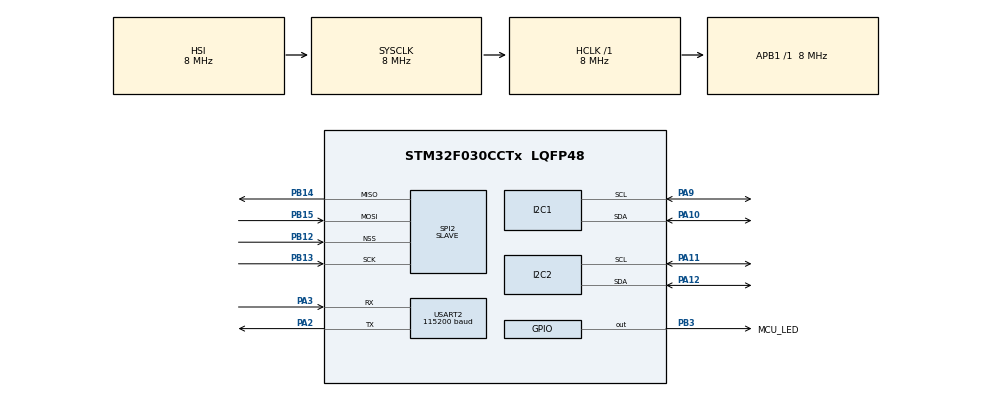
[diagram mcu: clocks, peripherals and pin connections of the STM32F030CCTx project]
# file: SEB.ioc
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I2C1.Timing=0x00201D2B
Mcu.Family=STM32F0
Mcu.Name=STM32F030CCTx
Mcu.Package=LQFP48
NVIC.SPI2_IRQn=true\:0\:0\:false\:false\:true\:true\:false\:false
PA10.Mode=I2C
PA10.Signal=I2C1_SDA
PA11.Mode=I2C
PA11.Signal=I2C2_SCL
PA12.Mode=I2C
PA12.Signal=I2C2_SDA
PA2.Mode=Asynchronous
PA2.Signal=USART2_TX
PA3.Mode=Asynchronous
PA3.Signal=USART2_RX
PA9.Mode=I2C
PA9.Signal=I2C1_SCL
PB12.GPIO_Mode=GPIO_MODE_AF_PP
PB12.GPIO_PuPd=GPIO_NOPULL
PB12.GPIO_Speed=GPIO_SPEED_FREQ_HIGH
PB12.Mode=NSS_Signal_Hard_Input
PB12.Signal=SPI2_NSS
PB13.GPIO_Mode=GPIO_MODE_AF_PP
PB13.GPIO_PuPd=GPIO_PULLDOWN
PB13.GPIO_Speed=GPIO_SPEED_FREQ_HIGH
PB13.Mode=Full_Duplex_Slave
PB13.Signal=SPI2_SCK
PB14.GPIO_Mode=GPIO_MODE_AF_PP
PB14.GPIO_PuPd=GPIO_NOPULL
PB14.GPIO_Speed=GPIO_SPEED_FREQ_HIGH
PB14.Mode=Full_Duplex_Slave
PB14.Signal=SPI2_MISO
PB15.GPIO_Mode=GPIO_MODE_AF_PP
PB15.GPIO_PuPd=GPIO_NOPULL
PB15.GPIO_Speed=GPIO_SPEED_FREQ_HIGH
PB15.Mode=Full_Duplex_Slave
PB15.Signal=SPI2_MOSI
PB3.GPIO_Label=MCU_LED
PB3.Signal=GPIO_Output
ProjectManager.HeapSize=0x200
ProjectManager.StackSize=0x400
ProjectManager.TargetToolchain=STM32CubeIDE
RCC.AHBFreq_Value=8000000
RCC.APB1Freq_Value=8000000
RCC.APB1TimFreq_Value=8000000
RCC.HCLKFreq_Value=8000000
RCC.HSE_VALUE=30000000
RCC.SYSCLKFreq_VALUE=8000000
SPI2.DataSize=SPI_DATASIZE_8BIT
SPI2.Direction=SPI_DIRECTION_2LINES
SPI2.Mode=SPI_MODE_SLAVE
SPI2.VirtualNSS=VM_NSSHARD
SPI2.VirtualType=VM_SLAVE
USART2.BaudRate=115200
USART2.SwapParam=ADVFEATURE_SWAP_ENABLE
USART2.VirtualMode-Asynchronous=VM_ASYNC
board=custom

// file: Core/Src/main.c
/* USER CODE BEGIN Header */
/**
  ******************************************************************************
  * @file           : main.c
  * @brief          : Main program body
  ******************************************************************************
  * @attention
  *
  * Copyright (c) 2024 STMicroelectronics.
  * All rights reserved.
  *
  * This software is licensed under terms that can be found in the LICENSE file
  * in the root directory of this software component.
  * If no LICENSE file comes with this software, it is provided AS-IS.
  *
  ******************************************************************************
  */
/* USER CODE END Header */
#include "main.h"

/* USER CODE BEGIN Includes */
#include "MS5611_SIM.h"
/* USER CODE END Includes */

I2C_HandleTypeDef hi2c1;
I2C_HandleTypeDef hi2c2;

SPI_HandleTypeDef hspi2;

UART_HandleTypeDef huart2;

void SystemClock_Config(void);
static void MX_GPIO_Init(void);
static void MX_USART2_UART_Init(void);
static void MX_I2C1_Init(void);
static void MX_I2C2_Init(void);
static void MX_SPI2_Init(void);

int main(void)
{

  /* MCU Configuration--------------------------------------------------------*/

  /* Reset of all peripherals, Initializes the Flash interface and the Systick. */
  HAL_Init();

  /* Configure the system clock */
  SystemClock_Config();

  /* Initialize all configured peripherals */
  MX_GPIO_Init();
  MX_USART2_UART_Init();
  MX_I2C1_Init();
  MX_I2C2_Init();
  MX_SPI2_Init();
  /* USER CODE BEGIN 2 */
  emulation_init();
  /* USER CODE END 2 */

  /* Infinite loop */
  while (1) {

  }
}

void SystemClock_Config(void)
{
  RCC_OscInitTypeDef RCC_OscInitStruct = {0};
  RCC_ClkInitTypeDef RCC_ClkInitStruct = {0};
  RCC_PeriphCLKInitTypeDef PeriphClkInit = {0};

  /** Initializes the RCC Oscillators according to the specified parameters
  * in the RCC_OscInitTypeDef structure.
  */
  RCC_OscInitStruct.OscillatorType = RCC_OSCILLATORTYPE_HSI;
  RCC_OscInitStruct.HSIState = RCC_HSI_ON;
  RCC_OscInitStruct.HSICalibrationValue = RCC_HSICALIBRATION_DEFAULT;
  RCC_OscInitStruct.PLL.PLLState = RCC_PLL_NONE;
  if (HAL_RCC_OscConfig(&RCC_OscInitStruct) != HAL_OK)
  {
    Error_Handler();
  }

  /** Initializes the CPU, AHB and APB buses clocks
  */
  RCC_ClkInitStruct.ClockType = RCC_CLOCKTYPE_HCLK|RCC_CLOCKTYPE_SYSCLK
                              |RCC_CLOCKTYPE_PCLK1;
  RCC_ClkInitStruct.SYSCLKSource = RCC_SYSCLKSOURCE_HSI;
  RCC_ClkInitStruct.AHBCLKDivider = RCC_SYSCLK_DIV1;
  RCC_ClkInitStruct.APB1CLKDivider = RCC_HCLK_DIV1;

  if (HAL_RCC_ClockConfig(&RCC_ClkInitStruct, FLASH_LATENCY_0) != HAL_OK)
  {
    Error_Handler();
  }
  PeriphClkInit.PeriphClockSelection = RCC_PERIPHCLK_I2C1;
  PeriphClkInit.I2c1ClockSelection = RCC_I2C1CLKSOURCE_HSI;
  if (HAL_RCCEx_PeriphCLKConfig(&PeriphClkInit) != HAL_OK)
  {
    Error_Handler();
  }
}

static void MX_I2C1_Init(void)
{

  hi2c1.Instance = I2C1;
  hi2c1.Init.Timing = 0x00201D2B;
  hi2c1.Init.OwnAddress1 = 0;
  hi2c1.Init.AddressingMode = I2C_ADDRESSINGMODE_7BIT;
  hi2c1.Init.DualAddressMode = I2C_DUALADDRESS_DISABLE;
  hi2c1.Init.OwnAddress2 = 0;
  hi2c1.Init.OwnAddress2Masks = I2C_OA2_NOMASK;
  hi2c1.Init.GeneralCallMode = I2C_GENERALCALL_DISABLE;
  hi2c1.Init.NoStretchMode = I2C_NOSTRETCH_DISABLE;
  if (HAL_I2C_Init(&hi2c1) != HAL_OK)
  {
    Error_Handler();
  }

  /** Configure Analogue filter
  */
  if (HAL_I2CEx_ConfigAnalogFilter(&hi2c1, I2C_ANALOGFILTER_ENABLE) != HAL_OK)
  {
    Error_Handler();
  }

  /** Configure Digital filter
  */
  if (HAL_I2CEx_ConfigDigitalFilter(&hi2c1, 0) != HAL_OK)
  {
    Error_Handler();
  }

}

static void MX_I2C2_Init(void)
{

  hi2c2.Instance = I2C2;
  hi2c2.Init.Timing = 0x2000090E;
  hi2c2.Init.OwnAddress1 = 0;
  hi2c2.Init.AddressingMode = I2C_ADDRESSINGMODE_7BIT;
  hi2c2.Init.DualAddressMode = I2C_DUALADDRESS_DISABLE;
  hi2c2.Init.OwnAddress2 = 0;
  hi2c2.Init.OwnAddress2Masks = I2C_OA2_NOMASK;
  hi2c2.Init.GeneralCallMode = I2C_GENERALCALL_DISABLE;
  hi2c2.Init.NoStretchMode = I2C_NOSTRETCH_DISABLE;
  if (HAL_I2C_Init(&hi2c2) != HAL_OK)
  {
    Error_Handler();
  }

  /** Configure Analogue filter
  */
  if (HAL_I2CEx_ConfigAnalogFilter(&hi2c2, I2C_ANALOGFILTER_ENABLE) != HAL_OK)
  {
    Error_Handler();
  }

  /** Configure Digital filter
  */
  if (HAL_I2CEx_ConfigDigitalFilter(&hi2c2, 0) != HAL_OK)
  {
    Error_Handler();
  }

}

static void MX_SPI2_Init(void)
{

  /* SPI2 parameter configuration*/
  hspi2.Instance = SPI2;
  hspi2.Init.Mode = SPI_MODE_SLAVE;
  hspi2.Init.Direction = SPI_DIRECTION_2LINES;
  hspi2.Init.DataSize = SPI_DATASIZE_8BIT;
  hspi2.Init.CLKPolarity = SPI_POLARITY_LOW;
  hspi2.Init.CLKPhase = SPI_PHASE_1EDGE;
  hspi2.Init.NSS = SPI_NSS_HARD_INPUT;
  hspi2.Init.FirstBit = SPI_FIRSTBIT_MSB;
  hspi2.Init.TIMode = SPI_TIMODE_DISABLE;
  hspi2.Init.CRCCalculation = SPI_CRCCALCULATION_DISABLE;
  hspi2.Init.CRCPolynomial = 7;
  hspi2.Init.CRCLength = SPI_CRC_LENGTH_DATASIZE;
  hspi2.Init.NSSPMode = SPI_NSS_PULSE_DISABLE;
  if (HAL_SPI_Init(&hspi2) != HAL_OK)
  {
    Error_Handler();
  }

}

static void MX_USART2_UART_Init(void)
{

  huart2.Instance = USART2;
  huart2.Init.BaudRate = 115200;
  huart2.Init.WordLength = UART_WORDLENGTH_8B;
  huart2.Init.StopBits = UART_STOPBITS_1;
  huart2.Init.Parity = UART_PARITY_NONE;
  huart2.Init.Mode = UART_MODE_TX_RX;
  huart2.Init.HwFlowCtl = UART_HWCONTROL_NONE;
  huart2.Init.OverSampling = UART_OVERSAMPLING_16;
  huart2.Init.OneBitSampling = UART_ONE_BIT_SAMPLE_DISABLE;
  huart2.AdvancedInit.AdvFeatureInit = UART_ADVFEATURE_SWAP_INIT;
  huart2.AdvancedInit.Swap = UART_ADVFEATURE_SWAP_ENABLE;
  if (HAL_UART_Init(&huart2) != HAL_OK)
  {
    Error_Handler();
  }

}

static void MX_GPIO_Init(void)
{
  GPIO_InitTypeDef GPIO_InitStruct = {0};

  /* GPIO Ports Clock Enable */
  __HAL_RCC_GPIOA_CLK_ENABLE();
  __HAL_RCC_GPIOB_CLK_ENABLE();

  /*Configure GPIO pin Output Level */
  HAL_GPIO_WritePin(MCU_LED_GPIO_Port, MCU_LED_Pin, GPIO_PIN_RESET);

  /*Configure GPIO pin : MCU_LED_Pin */
  GPIO_InitStruct.Pin = MCU_LED_Pin;
  GPIO_InitStruct.Mode = GPIO_MODE_OUTPUT_PP;
  GPIO_InitStruct.Pull = GPIO_NOPULL;
  GPIO_InitStruct.Speed = GPIO_SPEED_FREQ_LOW;
  HAL_GPIO_Init(MCU_LED_GPIO_Port, &GPIO_InitStruct);

}

void Error_Handler(void)
{
  __disable_irq();
  while (1)
  {
  }
}
